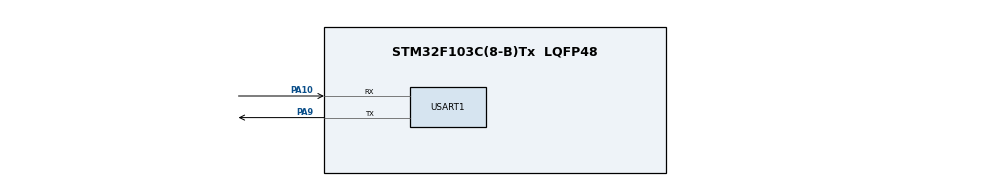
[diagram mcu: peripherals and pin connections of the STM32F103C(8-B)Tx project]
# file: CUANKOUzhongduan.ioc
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Mcu.Family=STM32F1
Mcu.Name=STM32F103C(8-B)Tx
Mcu.Package=LQFP48
NVIC.PriorityGroup=NVIC_PRIORITYGROUP_4
NVIC.USART1_IRQn=true\:0\:0\:false\:false\:true\:true\:true\:true
PA10.Mode=Asynchronous
PA10.Signal=USART1_RX
PA13.Mode=Serial_Wire
PA13.Signal=SYS_JTMS-SWDIO
PA14.Mode=Serial_Wire
PA14.Signal=SYS_JTCK-SWCLK
PA9.Mode=Asynchronous
PA9.Signal=USART1_TX
PD0-OSC_IN.Mode=HSE-External-Oscillator
PD0-OSC_IN.Signal=RCC_OSC_IN
PD1-OSC_OUT.Mode=HSE-External-Oscillator
PD1-OSC_OUT.Signal=RCC_OSC_OUT
ProjectManager.HeapSize=0x200
ProjectManager.StackSize=0x400
ProjectManager.TargetToolchain=MDK-ARM V5
RCC.APB1Freq_Value=8000000
RCC.APB2Freq_Value=8000000
USART1.VirtualMode=VM_ASYNC
board=custom

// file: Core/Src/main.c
/* USER CODE BEGIN Header */
/**
  ******************************************************************************
  * @file           : main.c
  * @brief          : Main program body
  ******************************************************************************
  * @attention
  *
  * Copyright (c) 2025 STMicroelectronics.
  * All rights reserved.
  *
  * This software is licensed under terms that can be found in the LICENSE file
  * in the root directory of this software component.
  * If no LICENSE file comes with this software, it is provided AS-IS.
  *
  ******************************************************************************
  */
/* USER CODE END Header */
#include "main.h"
#include "usart.h"
#include "gpio.h"

/* USER CODE BEGIN Includes */
#include <string.h>  // 用于字符串操作
/* USER CODE END Includes */

/* USER CODE BEGIN PD */
#define SEND_INTERVAL 1000  // 发送间隔，单位：毫秒
/* USER CODE END PD */

/* USER CODE BEGIN PV */
uint32_t last_send_time = 0;                  // 上次发送时间
uint8_t send_buffer[] = "hello windows!\r\n"; // 要发送的数据
uint8_t sending_in_progress = 0;              // 发送状态标志：0-空闲，1-发送中
/* USER CODE END PV */

void SystemClock_Config(void);
/* USER CODE BEGIN PFP */
void ScheduleUARTSend(void);  // 声明调度发送函数
/* USER CODE END PFP */

int main(void)
{

  /* MCU Configuration--------------------------------------------------------*/

  /* Reset of all peripherals, Initializes the Flash interface and the Systick. */
  HAL_Init();

  /* Configure the system clock */
  SystemClock_Config();

  /* Initialize all configured peripherals */
  MX_GPIO_Init();
  MX_USART1_UART_Init();
  /* USER CODE BEGIN 2 */
  last_send_time = HAL_GetTick();  // 初始化上次发送时间

  // 使能UART发送完成中断
  __HAL_UART_ENABLE_IT(&huart1, UART_IT_TXE);

  // 启动第一次发送
  ScheduleUARTSend();
  /* USER CODE END 2 */

  /* Infinite loop */
  while (1)
  {

    /* USER CODE BEGIN 3 */
    // 轮询检查是否到达下一次发送时间
    if (!sending_in_progress && (HAL_GetTick() - last_send_time >= SEND_INTERVAL))
    {
      ScheduleUARTSend();  // 调度发送
    }
  }
  /* USER CODE END 3 */
}

void SystemClock_Config(void)
{
  RCC_OscInitTypeDef RCC_OscInitStruct = {0};
  RCC_ClkInitTypeDef RCC_ClkInitStruct = {0};

  /** Initializes the RCC Oscillators according to the specified parameters
  * in the RCC_OscInitTypeDef structure.
  */
  RCC_OscInitStruct.OscillatorType = RCC_OSCILLATORTYPE_HSI;
  RCC_OscInitStruct.HSIState = RCC_HSI_ON;
  RCC_OscInitStruct.HSICalibrationValue = RCC_HSICALIBRATION_DEFAULT;
  RCC_OscInitStruct.PLL.PLLState = RCC_PLL_NONE;
  if (HAL_RCC_OscConfig(&RCC_OscInitStruct) != HAL_OK)
  {
    Error_Handler();
  }

  /** Initializes the CPU, AHB and APB buses clocks
  */
  RCC_ClkInitStruct.ClockType = RCC_CLOCKTYPE_HCLK|RCC_CLOCKTYPE_SYSCLK
                              |RCC_CLOCKTYPE_PCLK1|RCC_CLOCKTYPE_PCLK2;
  RCC_ClkInitStruct.SYSCLKSource = RCC_SYSCLKSOURCE_HSI;
  RCC_ClkInitStruct.AHBCLKDivider = RCC_SYSCLK_DIV1;
  RCC_ClkInitStruct.APB1CLKDivider = RCC_HCLK_DIV1;
  RCC_ClkInitStruct.APB2CLKDivider = RCC_HCLK_DIV1;

  if (HAL_RCC_ClockConfig(&RCC_ClkInitStruct, FLASH_LATENCY_0) != HAL_OK)
  {
    Error_Handler();
  }
}

/* USER CODE BEGIN 4 */
/**
  * @brief  调度UART发送
  * @param  无
  * @retval 无
  */
void ScheduleUARTSend(void)
{
  // 检查UART是否空闲
  if (HAL_UART_GetState(&huart1) == HAL_UART_STATE_READY)
  {
    sending_in_progress = 1;  // 设置发送状态为忙碌
    // 使用中断模式发送数据
    if (HAL_UART_Transmit_IT(&huart1, send_buffer, strlen((char*)send_buffer)) != HAL_OK)
    {
      Error_Handler();  // 发送启动失败处理
    }
  }
}

/**
  * @brief  UART发送完成回调函数
  * @param  huart: UART句柄
  * @retval 无
  */
void HAL_UART_TxCpltCallback(UART_HandleTypeDef *huart)
{
  if (huart == &huart1)
  {
    sending_in_progress = 0;  // 重置发送状态为空闲
    last_send_time = HAL_GetTick();  // 更新上次发送时间
  }
}
/* USER CODE END 4 */

void Error_Handler(void)
{
  /* USER CODE BEGIN Error_Handler_Debug */
  /* User can add his own implementation to report the HAL error return state */
  __disable_irq();
  while (1)
  {
    // 可以添加错误指示，例如LED闪烁
  }
  /* USER CODE END Error_Handler_Debug */
}
